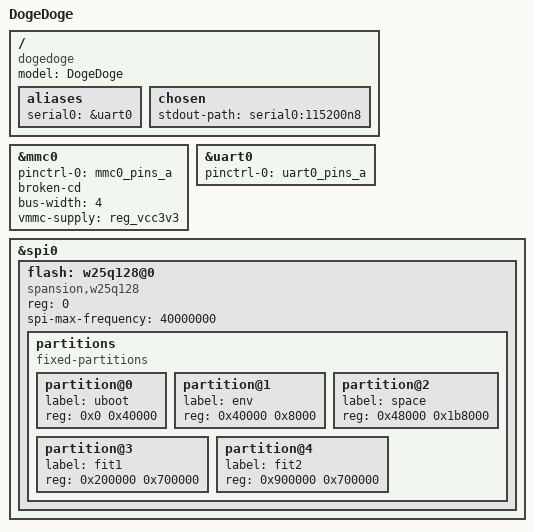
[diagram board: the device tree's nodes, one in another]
/dts-v1/;
#include "sun8i-v3s.dtsi"
#include "sunxi-common-regulators.dtsi"

/ {
	model = "DogeDoge";
	compatible = "dogedoge", "allwinner,sun8i-v3s";

	aliases {
		serial0 = &uart0;
	};

	chosen {
		stdout-path = "serial0:115200n8";
	};
};

&mmc0 {
	pinctrl-0 = <&mmc0_pins_a>;
	pinctrl-names = "default";
	broken-cd;
	bus-width = <4>;
	vmmc-supply = <&reg_vcc3v3>;
	status = "okay";
};

&uart0 {
	pinctrl-0 = <&uart0_pins_a>;
	pinctrl-names = "default";
	status = "okay";
};

&spi0 {
	status = "okay";
	flash: w25q128@0 {
		#address-cells = <1>;
		#size-cells = <1>;
		compatible = "spansion,w25q128", "jedec,spi-nor";
		reg = <0>;
		spi-max-frequency = <40000000>;
		partitions {
			compatible = "fixed-partitions";
			#address-cells = <1>;
			#size-cells = <1>;
			partition@0 {
				label = "uboot";
				reg = <0x0 0x40000>; // 256K
			};

			partition@1 {
				label = "env";
				reg = <0x40000 0x8000>; //32K
			};

			partition@2 {
				label = "space";
				reg = <0x48000 0x1b8000>; //1760K
			};

			partition@3 {
				label = "fit1";
				reg = <0x200000 0x700000>; //7MB
			};

			partition@4 {
				label = "fit2";
				reg = <0x900000 0x700000>; //7MB
			};
		};
	};
};
